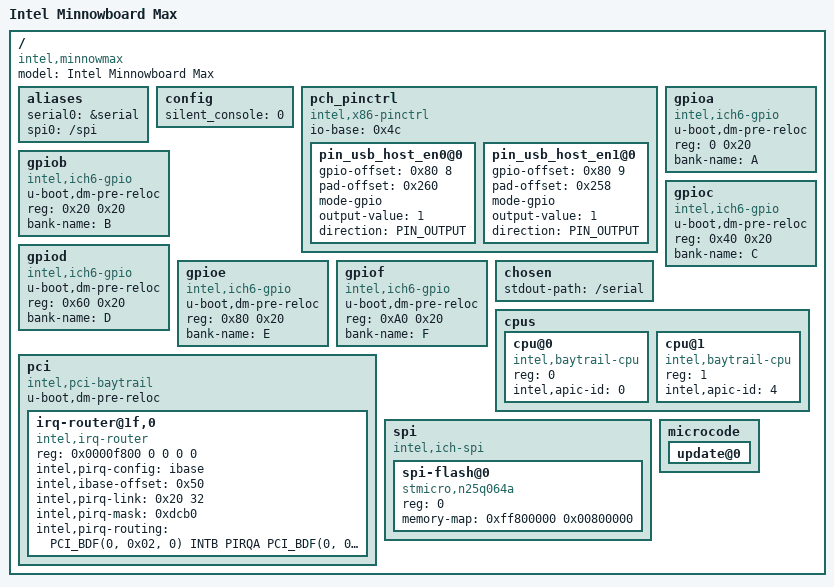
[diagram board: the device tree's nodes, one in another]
/*
 * Copyright (C) 2014, Bin Meng <bmeng.cn@gmail.com>
 *
 * SPDX-License-Identifier:	GPL-2.0+
 */

/dts-v1/;

#include <dt-bindings/gpio/x86-gpio.h>
#include <dt-bindings/interrupt-router/intel-irq.h>

/include/ "skeleton.dtsi"
/include/ "serial.dtsi"
/include/ "rtc.dtsi"

/ {
	model = "Intel Minnowboard Max";
	compatible = "intel,minnowmax", "intel,baytrail";

	aliases {
		serial0 = &serial;
		spi0 = "/spi";
	};

	config {
		silent_console = <0>;
	};

	pch_pinctrl {
		compatible = "intel,x86-pinctrl";
		io-base = <0x4c>;

		pin_usb_host_en0@0 {
			gpio-offset = <0x80 8>;
			pad-offset = <0x260>;
			mode-gpio;
			output-value = <1>;
			direction = <PIN_OUTPUT>;
		};

		pin_usb_host_en1@0 {
			gpio-offset = <0x80 9>;
			pad-offset = <0x258>;
			mode-gpio;
			output-value = <1>;
			direction = <PIN_OUTPUT>;
		};
	};

	gpioa {
		compatible = "intel,ich6-gpio";
		u-boot,dm-pre-reloc;
		reg = <0 0x20>;
		bank-name = "A";
	};

	gpiob {
		compatible = "intel,ich6-gpio";
		u-boot,dm-pre-reloc;
		reg = <0x20 0x20>;
		bank-name = "B";
	};

	gpioc {
		compatible = "intel,ich6-gpio";
		u-boot,dm-pre-reloc;
		reg = <0x40 0x20>;
		bank-name = "C";
	};

	gpiod {
		compatible = "intel,ich6-gpio";
		u-boot,dm-pre-reloc;
		reg = <0x60 0x20>;
		bank-name = "D";
	};

	gpioe {
		compatible = "intel,ich6-gpio";
		u-boot,dm-pre-reloc;
		reg = <0x80 0x20>;
		bank-name = "E";
	};

	gpiof {
		compatible = "intel,ich6-gpio";
		u-boot,dm-pre-reloc;
		reg = <0xA0 0x20>;
		bank-name = "F";
	};

	chosen {
		stdout-path = "/serial";
	};

	cpus {
		#address-cells = <1>;
		#size-cells = <0>;

		cpu@0 {
			device_type = "cpu";
			compatible = "intel,baytrail-cpu";
			reg = <0>;
			intel,apic-id = <0>;
		};

		cpu@1 {
			device_type = "cpu";
			compatible = "intel,baytrail-cpu";
			reg = <1>;
			intel,apic-id = <4>;
		};

	};

	pci {
		compatible = "intel,pci-baytrail", "pci-x86";
		#address-cells = <3>;
		#size-cells = <2>;
		u-boot,dm-pre-reloc;
		ranges = <0x02000000 0x0 0xd0000000 0xd0000000 0 0x10000000
			0x42000000 0x0 0xc0000000 0xc0000000 0 0x10000000
			0x01000000 0x0 0x2000 0x2000 0 0xe000>;

		irq-router@1f,0 {
			reg = <0x0000f800 0 0 0 0>;
			compatible = "intel,irq-router";
			intel,pirq-config = "ibase";
			intel,ibase-offset = <0x50>;
			intel,pirq-link = <0x20 32>;
			intel,pirq-mask = <0xdcb0>;
			intel,pirq-routing = <
				PCI_BDF(0, 0x02, 0) INTB PIRQA
				PCI_BDF(0, 0x10, 0) INTA PIRQD
				PCI_BDF(0, 0x11, 0) INTA PIRQB
				PCI_BDF(0, 0x12, 0) INTA PIRQC
				PCI_BDF(0, 0x13, 0) INTA PIRQD
				PCI_BDF(0, 0x14, 0) INTA PIRQE
				PCI_BDF(0, 0x15, 0) INTC PIRQF
				PCI_BDF(0, 0x17, 0) INTA PIRQF
				PCI_BDF(0, 0x18, 0) INTA PIRQB
				PCI_BDF(0, 0x1a, 0) INTA PIRQF
				PCI_BDF(0, 0x1b, 0) INTA PIRQG
				PCI_BDF(0, 0x1c, 0) INTD PIRQE
				PCI_BDF(0, 0x1d, 0) INTA PIRQD
				PCI_BDF(0, 0x1e, 0) INTB PIRQB
				PCI_BDF(0, 0x1f, 0) INTC PIRQH
			>;
		};
	};

	spi {
		#address-cells = <1>;
		#size-cells = <0>;
		compatible = "intel,ich-spi";
		spi-flash@0 {
			reg = <0>;
			compatible = "stmicro,n25q064a", "spi-flash";
			memory-map = <0xff800000 0x00800000>;
		};
	};

	microcode {
		update@0 {
#include "microcode/m0130673322.dtsi"
		};
	};

};
